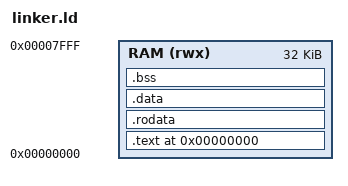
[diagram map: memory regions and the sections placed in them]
ENTRY(_start)

MEMORY {
    RAM (rwx) : ORIGIN = 0x00000000, LENGTH = 32K
}

SECTIONS {
    . = ORIGIN(RAM);
    .text : {
        *(.text.start)
        *(.text*)
    } > RAM
    .rodata : { *(.rodata*) } > RAM
    .data : { *(.data*) } > RAM
    .bss : {
        _bss_start = .;
        *(.bss*)
        _bss_end = .;
    } > RAM
    _stack_top = ORIGIN(RAM) + LENGTH(RAM);
}
